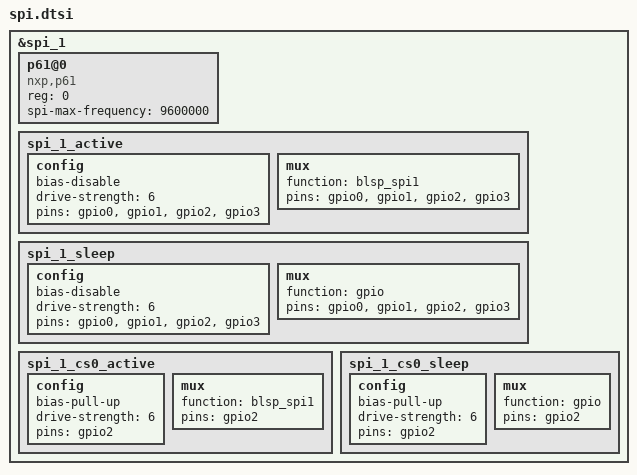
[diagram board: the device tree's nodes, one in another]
/*
 * Copyright (c) 2024, The Linux Foundation. All rights reserved.
 *
 * This program is free software; you can redistribute it and/or modify
 * it under the terms of the GNU General Public License version 2 and
 * only version 2 as published by the Free Software Foundation.
 *
 * This program is distributed in the hope that it will be useful,
 * but WITHOUT ANY WARRANTY; without even the implied warranty of
 * MERCHANTABILITY or FITNESS FOR A PARTICULAR PURPOSE.  See the
 * GNU General Public License for more details.
 */

&spi_1 {
	status = "ok";

	p61@0 {
		compatible = "nxp,p61";
		reg = <0>;
		spi-max-frequency = <9600000>;
	};

	spi_1_active: spi_1_active {
		config {
			bias-disable;
			drive-strength = <6>;
			pins = "gpio0", "gpio1", "gpio2", "gpio3";
		};

		mux {
			function = "blsp_spi1";
			pins = "gpio0", "gpio1", "gpio2", "gpio3";
		};
	};

	spi_1_sleep: spi_1_sleep {
		config {
			bias-disable;
			drive-strength = <6>;
			pins = "gpio0", "gpio1", "gpio2", "gpio3";
		};

		mux {
			function = "gpio";
			pins = "gpio0", "gpio1", "gpio2", "gpio3";
		};
	};

	spi_1_cs0_active: spi_1_cs0_active {
		config {
			bias-pull-up;
			drive-strength = <6>;
			pins = "gpio2";
		};

		mux {
			function = "blsp_spi1";
			pins = "gpio2";
		};
	};

	spi_1_cs0_sleep: spi_1_cs0_sleep {
		config {
			bias-pull-up;
			drive-strength = <6>;
			pins = "gpio2";
		};

		mux {
			function = "gpio";
			pins = "gpio2";
		};
	};
};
